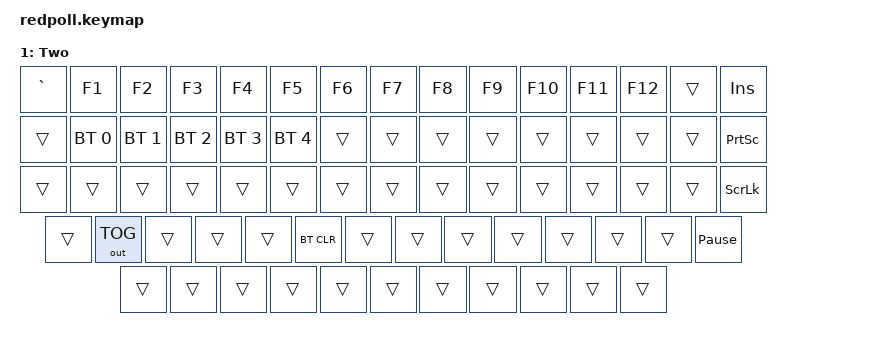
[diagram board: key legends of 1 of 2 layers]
/*
 * build firmware locally:
 *   cd github/zmk/app
 *   west build -b nice_nano_v2 -- -DSHIELD=redpoll
     ;; reset controller
 *   cp build/zephyr/zmk.uf2 /media/.../NICENANO/
 */

#include <behaviors.dtsi>
#include <dt-bindings/zmk/bt.h>
#include <dt-bindings/zmk/keys.h>
#include "keys_de.h"

/ {
    combos {
        compatible = "zmk,combos";

        GREATERTHAN {
            bindings = <&kp DE_GT>;
            key-positions = <38 39>;//figure out if I need any of these
            layers = <1>;
            timeout-ms = <20>;
        };
    };

    keymap {
        compatible = "zmk,keymap";

  

        base {
            bindings = <
                            &kp ESC   &kp N1    &kp N2    &kp N3    &kp N4    &kp N5    &kp N6  &kp N7 &kp N7  &kp N8    &kp N9    &kp N0    &kp MINUS &kp EQUAL &kp BSPC  
                            &kp TAB     &kp Q     &kp W     &kp E     &kp R     &kp T     &kp Y     &kp U     &kp I     &kp O     &kp P     &kp LBKT   &kp RBKT  &kp BSLH 
                            &kp CAPS     &kp A     &kp S     &kp D     &kp F     &kp G     &kp H     &kp J     &kp K     &kp L     &kp SEMI  &kp SQT    &kp RET   &kp PG_UP &kp END
                            &kp LSHFT      &kp Z     &kp X     &kp C     &kp V     &kp B  &kp RCTRL  &kp N     &kp M     &kp COMMA &kp DOT   &kp FSLH  &kp RSHFT           
                            &kp LCTRL &mo LOWER &kp LGUI  &kp LALT              &kp SPACE           &kp RALT &kp LGUI                       &kp LEFT  &kp DOWN &kp UP &kp RIGHT
                        >;

            label = "Base";
        };

        two {// Not modified
            bindings = <
                            &kp GRAVE &kp F1    &kp F2    &kp F3    &kp F4    &kp F5    &kp F6    &kp F7    &kp F8    &kp F9    &kp F10   &kp F11   &kp F12   &trans    &kp INS
                            &trans     &bt BT_SEL 0 &bt BT_SEL 1 &bt BT_SEL 2 &bt BT_SEL 3 &bt BT_SEL 4 &trans &trans &trans    &trans    &trans    &trans    &trans    &trans    &kp PSCRN
                            &trans      &trans    &trans    &trans    &trans    &trans    &trans    &trans    &trans    &trans    &trans    &trans    &trans    &trans    &kp SLCK
                            &trans        &out OUT_TOG &trans &trans  &trans    &bt BT_CLR &trans   &trans    &trans    &trans    &trans    &trans              &trans    &kp PAUSE_BREAK
                            &trans    &trans    &trans    &trans              &trans                &trans    &trans    &trans                          &trans    &trans    &trans
                        >;

            label = "Two";
        };

    };
};
